# CY8C5868LTI_LP039 register map
File version: 0.1
Registers are 8-bit, read-write, no defined reset value unless marked. A register's access mark holds for its fields unless they carry their own. Offsets are from the block's base; [hi:lo] are bit positions; 'fields as' and 'values as' point back to an identical list.

## PWMSB
Base 0x00000000
0x40006524 PWMSB_COMPARE_Reg_ — UDB.D0 - Assigned Compare Value
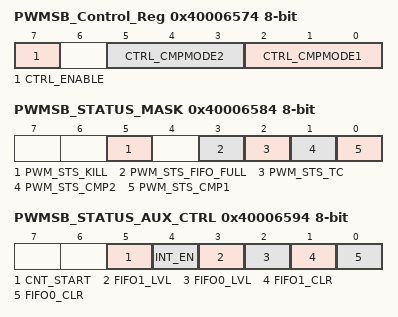
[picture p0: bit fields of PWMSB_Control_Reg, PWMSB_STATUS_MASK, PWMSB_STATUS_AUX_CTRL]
0x40006574 PWMSB_Control_Reg — UDB Control Register - Assigned Control Register Value
  [7] CTRL_ENABLE — Enable the PWM
  [5:3] CTRL_CMPMODE2 — Compare mode 2
  [2:0] CTRL_CMPMODE1 — Compare mode 1
0x40006584 PWMSB_STATUS_MASK — UDB Status bits Interrupt Mask Enable Register
  [5] PWM_STS_KILL ro — Enables the Interrupt on Kill
  [3] PWM_STS_FIFO_FULL ro — FIFO Full Status Mask
  [2] PWM_STS_TC ro — Enables the Interrupt on Terminal Count
  [1] PWM_STS_CMP2 ro — Enables the Interrupt on Compare 2
  [0] PWM_STS_CMP1 ro — Enables the Interrupt on Compare 1
0x40006594 PWMSB_STATUS_AUX_CTRL — UDB Auxilliary Control Register
  [5] CNT_START — FIFO0 clear
    0=E_CNT_START0 (Disable counter); 1=E_CNT_START1 (Enable counter)
  [4] INT_EN
    0=E_INT_EN0 (Interrupt disabled); 1=E_INT_EN1 (Interrupt enabled)
  [3] FIFO1_LVL — FIFO level
    0=E_FIFO_LVL_0 (FIFO LVL: input mode: FIFO not full; output mode: FIFO not empty); 1=E_FIFO_LVL_1 (FIFO LVL: input mode: FIFO at least 1/2 empty; output mode: FIFO at least 1/2 full)
  [2] FIFO0_LVL — FIFO level
    values as FIFO1_LVL
  [1] FIFO1_CLR — FIFO1 clear
    0=E_FIFO_CLR_0 (Normal FIFO operation); 1=E_FIFO_CLR_1 (Clear FIFO state)
  [0] FIFO0_CLR — FIFO0 clear
    values as FIFO1_CLR

## PWMF1
Base 0x00000000
0x40006426 PWMF1_COMPARE_Reg_ — UDB.D0 - Assigned Compare Value
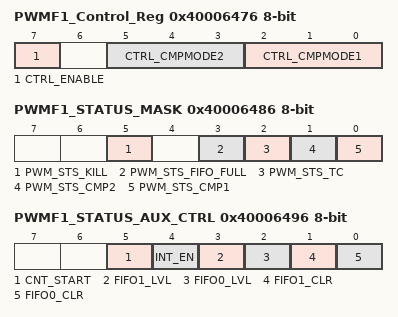
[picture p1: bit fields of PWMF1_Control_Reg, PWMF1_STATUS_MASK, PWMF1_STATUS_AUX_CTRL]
0x40006476 PWMF1_Control_Reg — UDB Control Register - Assigned Control Register Value
  [7] CTRL_ENABLE — Enable the PWM
  [5:3] CTRL_CMPMODE2 — Compare mode 2
  [2:0] CTRL_CMPMODE1 — Compare mode 1
0x40006486 PWMF1_STATUS_MASK — UDB Status bits Interrupt Mask Enable Register
  [5] PWM_STS_KILL ro — Enables the Interrupt on Kill
  [3] PWM_STS_FIFO_FULL ro — FIFO Full Status Mask
  [2] PWM_STS_TC ro — Enables the Interrupt on Terminal Count
  [1] PWM_STS_CMP2 ro — Enables the Interrupt on Compare 2
  [0] PWM_STS_CMP1 ro — Enables the Interrupt on Compare 1
0x40006496 PWMF1_STATUS_AUX_CTRL — UDB Auxilliary Control Register
  [5] CNT_START — FIFO0 clear
    0=E_CNT_START0 (Disable counter); 1=E_CNT_START1 (Enable counter)
  [4] INT_EN
    0=E_INT_EN0 (Interrupt disabled); 1=E_INT_EN1 (Interrupt enabled)
  [3] FIFO1_LVL — FIFO level
    0=E_FIFO_LVL_0 (FIFO LVL: input mode: FIFO not full; output mode: FIFO not empty); 1=E_FIFO_LVL_1 (FIFO LVL: input mode: FIFO at least 1/2 empty; output mode: FIFO at least 1/2 full)
  [2] FIFO0_LVL — FIFO level
    values as FIFO1_LVL
  [1] FIFO1_CLR — FIFO1 clear
    0=E_FIFO_CLR_0 (Normal FIFO operation); 1=E_FIFO_CLR_1 (Clear FIFO state)
  [0] FIFO0_CLR — FIFO0 clear
    values as FIFO1_CLR

## PWMSF
Base 0x00000000
0x40006525 PWMSF_COMPARE_Reg_ — UDB.D0 - Assigned Compare Value
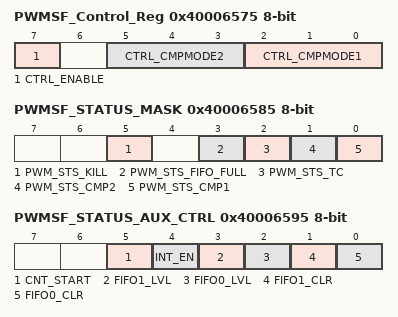
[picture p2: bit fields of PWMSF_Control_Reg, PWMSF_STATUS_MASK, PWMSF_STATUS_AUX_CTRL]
0x40006575 PWMSF_Control_Reg — UDB Control Register - Assigned Control Register Value
  [7] CTRL_ENABLE — Enable the PWM
  [5:3] CTRL_CMPMODE2 — Compare mode 2
  [2:0] CTRL_CMPMODE1 — Compare mode 1
0x40006585 PWMSF_STATUS_MASK — UDB Status bits Interrupt Mask Enable Register
  [5] PWM_STS_KILL ro — Enables the Interrupt on Kill
  [3] PWM_STS_FIFO_FULL ro — FIFO Full Status Mask
  [2] PWM_STS_TC ro — Enables the Interrupt on Terminal Count
  [1] PWM_STS_CMP2 ro — Enables the Interrupt on Compare 2
  [0] PWM_STS_CMP1 ro — Enables the Interrupt on Compare 1
0x40006595 PWMSF_STATUS_AUX_CTRL — UDB Auxilliary Control Register
  [5] CNT_START — FIFO0 clear
    0=E_CNT_START0 (Disable counter); 1=E_CNT_START1 (Enable counter)
  [4] INT_EN
    0=E_INT_EN0 (Interrupt disabled); 1=E_INT_EN1 (Interrupt enabled)
  [3] FIFO1_LVL — FIFO level
    0=E_FIFO_LVL_0 (FIFO LVL: input mode: FIFO not full; output mode: FIFO not empty); 1=E_FIFO_LVL_1 (FIFO LVL: input mode: FIFO at least 1/2 empty; output mode: FIFO at least 1/2 full)
  [2] FIFO0_LVL — FIFO level
    values as FIFO1_LVL
  [1] FIFO1_CLR — FIFO1 clear
    0=E_FIFO_CLR_0 (Normal FIFO operation); 1=E_FIFO_CLR_1 (Clear FIFO state)
  [0] FIFO0_CLR — FIFO0 clear
    values as FIFO1_CLR

## PWMF2
Base 0x00000000
0x40006427 PWMF2_COMPARE_Reg_ — UDB.D0 - Assigned Compare Value
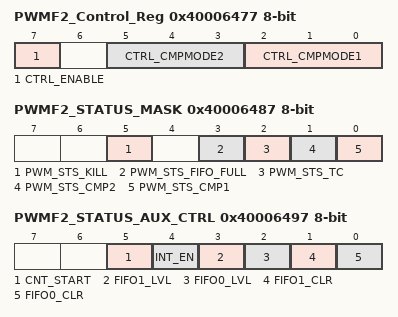
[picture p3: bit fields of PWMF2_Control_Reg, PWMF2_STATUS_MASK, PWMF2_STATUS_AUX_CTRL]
0x40006477 PWMF2_Control_Reg — UDB Control Register - Assigned Control Register Value
  [7] CTRL_ENABLE — Enable the PWM
  [5:3] CTRL_CMPMODE2 — Compare mode 2
  [2:0] CTRL_CMPMODE1 — Compare mode 1
0x40006487 PWMF2_STATUS_MASK — UDB Status bits Interrupt Mask Enable Register
  [5] PWM_STS_KILL ro — Enables the Interrupt on Kill
  [3] PWM_STS_FIFO_FULL ro — FIFO Full Status Mask
  [2] PWM_STS_TC ro — Enables the Interrupt on Terminal Count
  [1] PWM_STS_CMP2 ro — Enables the Interrupt on Compare 2
  [0] PWM_STS_CMP1 ro — Enables the Interrupt on Compare 1
0x40006497 PWMF2_STATUS_AUX_CTRL — UDB Auxilliary Control Register
  [5] CNT_START — FIFO0 clear
    0=E_CNT_START0 (Disable counter); 1=E_CNT_START1 (Enable counter)
  [4] INT_EN
    0=E_INT_EN0 (Interrupt disabled); 1=E_INT_EN1 (Interrupt enabled)
  [3] FIFO1_LVL — FIFO level
    0=E_FIFO_LVL_0 (FIFO LVL: input mode: FIFO not full; output mode: FIFO not empty); 1=E_FIFO_LVL_1 (FIFO LVL: input mode: FIFO at least 1/2 empty; output mode: FIFO at least 1/2 full)
  [2] FIFO0_LVL — FIFO level
    values as FIFO1_LVL
  [1] FIFO1_CLR — FIFO1 clear
    0=E_FIFO_CLR_0 (Normal FIFO operation); 1=E_FIFO_CLR_1 (Clear FIFO state)
  [0] FIFO0_CLR — FIFO0 clear
    values as FIFO1_CLR

## CounterF
Base 0x00000000
0x40006405 CounterF_COUNTER — UDB.A0 - Current Counter Value
0x40006425 CounterF_PERIOD — UDB.D0 - Assigned Period
0x40006435 CounterF_COMPARE — UDB.D1 - Assigned Compare Value
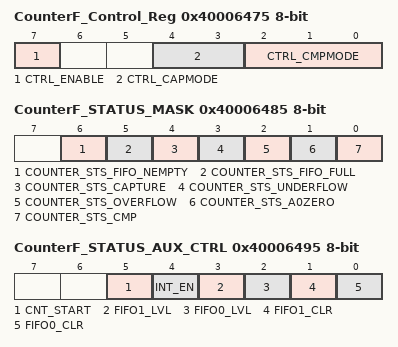
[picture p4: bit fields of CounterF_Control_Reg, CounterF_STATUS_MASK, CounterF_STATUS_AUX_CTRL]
0x40006475 CounterF_Control_Reg — UDB Control Register - Assigned Control Register Value
  [7] CTRL_ENABLE — Enable Counter
  [4:3] CTRL_CAPMODE — Capture mode
  [2:0] CTRL_CMPMODE — Compare mode
0x40006485 CounterF_STATUS_MASK — UDB Status bits Interrupt Mask Enable Register
  [6] COUNTER_STS_FIFO_NEMPTY — FIFO Not Empty Status
  [5] COUNTER_STS_FIFO_FULL — FIFO Full Status
  [4] COUNTER_STS_CAPTURE — Capture Status
  [3] COUNTER_STS_UNDERFLOW — Underflow status
  [2] COUNTER_STS_OVERFLOW — Overflow status
  [1] COUNTER_STS_A0ZERO — A0 Zero ouput status
  [0] COUNTER_STS_CMP — Compare output status
0x40006495 CounterF_STATUS_AUX_CTRL — UDB Auxilliary Control Register
  [5] CNT_START — FIFO0 clear
    0=E_CNT_START0 (Disable counter); 1=E_CNT_START1 (Enable counter)
  [4] INT_EN
    0=E_INT_EN0 (Interrupt disabled); 1=E_INT_EN1 (Interrupt enabled)
  [3] FIFO1_LVL — FIFO level
    0=E_FIFO_LVL_0 (FIFO LVL: input mode: FIFO not full; output mode: FIFO not empty); 1=E_FIFO_LVL_1 (FIFO LVL: input mode: FIFO at least 1/2 empty; output mode: FIFO at least 1/2 full)
  [2] FIFO0_LVL — FIFO level
    values as FIFO1_LVL
  [1] FIFO1_CLR — FIFO1 clear
    0=E_FIFO_CLR_0 (Normal FIFO operation); 1=E_FIFO_CLR_1 (Clear FIFO state)
  [0] FIFO0_CLR — FIFO0 clear
    values as FIFO1_CLR
